# STM32L151 register map
File version: 1.6
CPU: CM3 r1p1, little endian, no MPU, no FPU, 4 interrupt priority bits
Registers are 32-bit, read-write, reset 0x0 unless marked. A register's access mark holds for its fields unless they carry their own. Offsets are from the block's base; [hi:lo] are bit positions; lines under a group give offsets from that group; {n}, {i} and the like mark numbered series; 'fields as' and 'values as' point back to an identical list.

## AES — Advanced encrytion standard hardware accelerator
Base 0x50060000
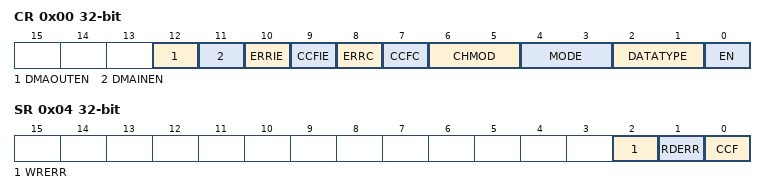
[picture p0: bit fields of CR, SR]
0x00 CR — control register
  [12] DMAOUTEN — Enable DMA management of data output phase
    0=Disable DMA Output; 1=Enabled DMA Output
  [11] DMAINEN — Enable DMA management of data input phase
    0=Disable DMA Input; 1=Enable DMA Input
  [10] ERRIE — Error interrupt enable
    0=Disabled (Disable (mask) error interrupt); 1=Enabled (Enable error interrupt)
  [9] CCFIE — CCF flag interrupt enable
    0=Disabled (Disable (mask) CCF interrupt); 1=Enabled (Enable CCF interrupt)
  [8] ERRC — Error clear
    on write: 1=Clear RDERR and WRERR flags
  [7] CCFC — Computation Complete Flag Clear
    on write: 1=Clear computation complete flag
  [6:5] CHMOD — AES chaining mode
    0=ECB (Electronic codebook (ECB)); 1=CBC (Cipher-Block Chaining (CBC)); 2=CTR (Counter Mode (CTR))
  [4:3] MODE — AES operating mode
    0=Mode 1: encryption; 1=Mode 2: key derivation (or key preparation for ECB/CBC decryption); 2=Mode 3: decryption; 3=Mode 4: key derivation then single decryption
  [2:1] DATATYPE — Data type selection
    0=None (Word); 1=Half-word (16-bit); 2=Byte (8-bit); 3=Bit
  [0] EN — AES enable
    0=Disabled (Disable AES); 1=Enabled (Enable AES)
0x04 SR ro — Status register
  [2] WRERR — Write error flag
    0=NoError (Write error not detected); 1=Error (Write error detected)
  [1] RDERR — Read error flag
    0=NoError (Read error not detected); 1=Error (Read error detected)
  [0] CCF — Computation complete flag
    0=Complete (Computation complete); 1=NotComplete (Computation not complete)
0x08 DINR — Data input register
  [31:0] DIN — Data input
0x0C DOUTR ro — Data output register
  [31:0] DOUT — Data output
{0x10+4i} KEYR{i} (i=0..3) — AES Key register {i}
  [31:0] KEY — AES key
{0x20+4i} IVR{i} (i=0..3) — Initialization Vector Register {i}
  [31:0] IVI — Initialization Vector Register

## COMP — Comparators
Base 0x40007C00
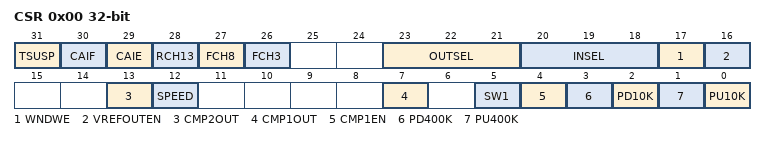
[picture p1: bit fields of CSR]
0x00 CSR access per field — comparator control and status register
  [31] TSUSP rw — Suspend Timer Mode
  [30] CAIF ro — Channel acquisition interrupt flag
  [29] CAIE rw — Channel Acquisition Interrupt Enable / Clear
  [28] RCH13 rw — Select GPIO port PC3 as re-routed ADC input channel CH13.
  [27] FCH8 rw — Select GPIO port PB0 as fast ADC input channel CH8.
  [26] FCH3 rw — Select GPIO port PA3 as fast ADC input channel CH3.
  [23:21] OUTSEL rw — Comparator 2 output selection
  [20:18] INSEL rw — Inverted input selection
  [17] WNDWE rw — Window mode enable
  [16] VREFOUTEN rw — VREFINT output enable
  [13] CMP2OUT ro — Comparator 2 output
  [12] SPEED rw — Comparator 2 speed mode
  [7] CMP1OUT ro — Comparator 1 output
  [5] SW1 rw — SW1 analog switch enable
  [4] CMP1EN rw — Comparator 1 enable
  [3] PD400K rw — 400 kO pull-down resistor
  [2] PD10K rw — 10 kO pull-down resistor
  [1] PU400K rw — 400 kO pull-up resistor
  [0] PU10K rw — 10 kO pull-up resistor

## CRC — CRC calculation unit
Base 0x40023000
0x00 DR reset 0xFFFFFFFF — Data register
  [31:0] DR — Data Register
0x04 IDR — Independent data register
  [7:0] IDR
0x08 CR wo — Control register
  [0] RESET
    1=Resets the CRC calculation unit and sets the data register to 0xFFFF FFFF

## DMA1 — Direct memory access controller
Base 0x40026000
Same registers: DMA2 0x40026400
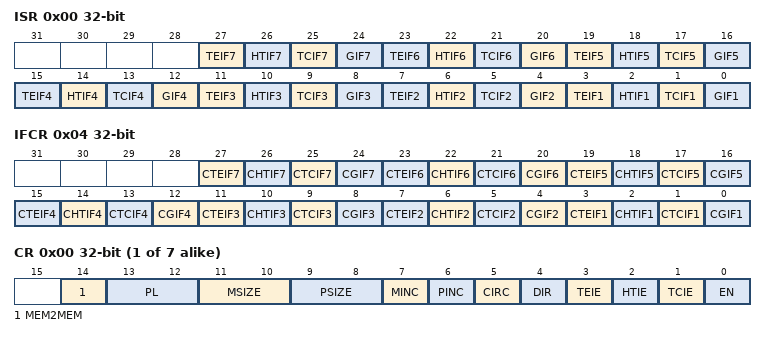
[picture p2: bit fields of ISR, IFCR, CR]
0x00 ISR ro — interrupt status register
  [4n-1] TEIF{n} (n=1..7) — Channel {n} Transfer Error flag
    0=NoError (No transfer error); 1=Error (A transfer error has occured)
  [4n-2] HTIF{n} (n=1..7) — Channel {n} Half Transfer Complete flag
    0=NotHalf (No half transfer event); 1=Half (A half transfer event has occured)
  [4n-3] TCIF{n} (n=1..7) — Channel {n} Transfer Complete flag
    0=NotComplete (No transfer complete event); 1=Complete (A transfer complete event has occured)
  [4n-4] GIF{n} (n=1..7) — Channel {n} Global interrupt flag
    0=NoEvent (No transfer error, half event, complete event); 1=Event (A transfer error, half event or complete event has occured)
0x04 IFCR wo — interrupt flag clear register
  [4n-1] CTEIF{n} (n=1..7) — Channel {n} Transfer Error clear
    1=Clears the TEIF flag in the ISR register
  [4n-2] CHTIF{n} (n=1..7) — Channel {n} Half Transfer clear
    1=Clears the HTIF flag in the ISR register
  [4n-3] CTCIF{n} (n=1..7) — Channel {n} Transfer Complete clear
    1=Clears the TCIF flag in the ISR register
  [4n-4] CGIF{n} (n=1..7) — Channel {n} Global interrupt clear
    1=Clears the GIF, TEIF, HTIF, TCIF flags in the ISR register
0x08 CH{i} (i=1..7; step 0x14) group — Channel cluster: CCR?, CNDTR?, CPAR?, and CMAR? registers
  0x00 CR — channel x configuration register
    [14] MEM2MEM — Memory to memory mode
      0=Disabled (Memory to memory mode disabled); 1=Enabled (Memory to memory mode enabled)
    [13:12] PL — Channel priority level
      0=Low (Low priority); 1=Medium priority; 2=High priority; 3=Very high priority
    [11:10] MSIZE — Memory size
      0=Bits8 (8-bit size); 1=Bits16 (16-bit size); 2=Bits32 (32-bit size)
    [9:8] PSIZE — Peripheral size
      values as MSIZE
    [7] MINC — Memory increment mode
      0=Disabled (Increment mode disabled); 1=Enabled (Increment mode enabled)
    [6] PINC — Peripheral increment mode
      values as MINC
    [5] CIRC — Circular mode
      0=Disabled (Circular buffer disabled); 1=Enabled (Circular buffer enabled)
    [4] DIR — Data transfer direction
      0=FromPeripheral (Read from peripheral); 1=FromMemory (Read from memory)
    [3] TEIE — Transfer error interrupt enable
      0=Disabled (Transfer Error interrupt disabled); 1=Enabled (Transfer Error interrupt enabled)
    [2] HTIE — Half transfer interrupt enable
      0=Disabled (Half Transfer interrupt disabled); 1=Enabled (Half Transfer interrupt enabled)
    [1] TCIE — Transfer complete interrupt enable
      0=Disabled (Transfer Complete interrupt disabled); 1=Enabled (Transfer Complete interrupt enabled)
    [0] EN — Channel enable
      0=Disabled (Channel disabled); 1=Enabled (Channel enabled)
  0x04 NDTR — channel x number of data register
    [15:0] NDT — Number of data to transfer
  0x08 PAR — channel x peripheral address register
    [31:0] PA — Peripheral address
  0x0C MAR — channel x memory address register
    [31:0] MA — Memory address
